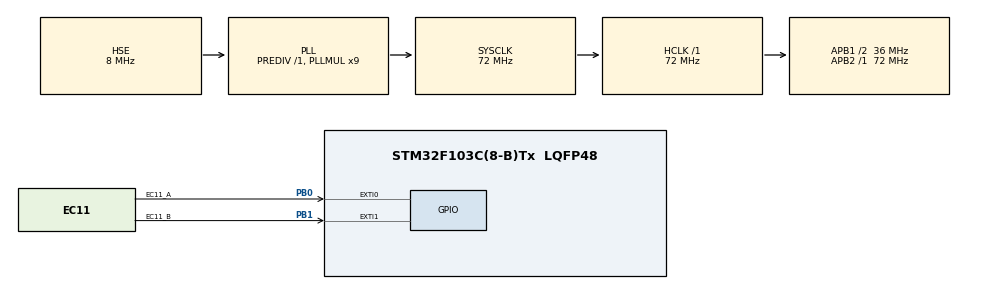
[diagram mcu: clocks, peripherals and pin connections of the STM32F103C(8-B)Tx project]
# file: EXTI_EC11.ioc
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Mcu.Family=STM32F1
Mcu.Name=STM32F103C(8-B)Tx
Mcu.Package=LQFP48
NVIC.EXTI0_IRQn=true\:0\:0\:false\:false\:true\:true\:true\:true
NVIC.EXTI1_IRQn=true\:0\:0\:false\:false\:true\:true\:true\:true
NVIC.PriorityGroup=NVIC_PRIORITYGROUP_4
PA13.Mode=Serial_Wire
PA13.Signal=SYS_JTMS-SWDIO
PA14.Mode=Serial_Wire
PA14.Signal=SYS_JTCK-SWCLK
PB0.GPIO_Label=EC11_A
PB0.GPIO_ModeDefaultEXTI=GPIO_MODE_IT_RISING_FALLING
PB0.GPIO_PuPd=GPIO_PULLUP
PB0.Signal=GPXTI0
PB1.GPIO_Label=EC11_B
PB1.GPIO_ModeDefaultEXTI=GPIO_MODE_IT_RISING_FALLING
PB1.GPIO_PuPd=GPIO_PULLUP
PB1.Signal=GPXTI1
PC14-OSC32_IN.Mode=LSE-External-Oscillator
PC14-OSC32_IN.Signal=RCC_OSC32_IN
PC15-OSC32_OUT.Mode=LSE-External-Oscillator
PC15-OSC32_OUT.Signal=RCC_OSC32_OUT
PD0-OSC_IN.Mode=HSE-External-Oscillator
PD0-OSC_IN.Signal=RCC_OSC_IN
PD1-OSC_OUT.Mode=HSE-External-Oscillator
PD1-OSC_OUT.Signal=RCC_OSC_OUT
ProjectManager.HeapSize=0x200
ProjectManager.StackSize=0x400
ProjectManager.TargetToolchain=CMake
RCC.AHBFreq_Value=72000000
RCC.APB1CLKDivider=RCC_HCLK_DIV2
RCC.APB1Freq_Value=36000000
RCC.APB1TimFreq_Value=72000000
RCC.APB2Freq_Value=72000000
RCC.APB2TimFreq_Value=72000000
RCC.HCLKFreq_Value=72000000
RCC.PLLMUL=RCC_PLL_MUL9
RCC.PLLSourceVirtual=RCC_PLLSOURCE_HSE
RCC.SYSCLKFreq_VALUE=72000000
RCC.SYSCLKSource=RCC_SYSCLKSOURCE_PLLCLK
RCC.USBFreq_Value=72000000
board=custom

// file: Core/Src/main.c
/* USER CODE BEGIN Header */
/**
  ******************************************************************************
  * @file           : main.c
  * @brief          : Main program body
  ******************************************************************************
  * @attention
  *
  * Copyright (c) 2026 STMicroelectronics.
  * All rights reserved.
  *
  * This software is licensed under terms that can be found in the LICENSE file
  * in the root directory of this software component.
  * If no LICENSE file comes with this software, it is provided AS-IS.
  *
  ******************************************************************************
  */
/* USER CODE END Header */
#include "main.h"
#include "gpio.h"
#include "OLED.h"

/* USER CODE BEGIN PV */
static volatile int32_t EC11_Count = 0;
static volatile int8_t EC11_QuarterSteps = 0;
static uint8_t EC11_PreviousState = 0;
static uint32_t lastDisplayTick = 0;

/* USER CODE END PV */

void SystemClock_Config(void);

int main(void) {

    /* MCU Configuration--------------------------------------------------------*/

    /* Reset of all peripherals, Initializes the Flash interface and the Systick. */
    HAL_Init();

    /* Configure the system clock */
    SystemClock_Config();

    /* Initialize all configured peripherals */
    MX_GPIO_Init();
    /* USER CODE BEGIN 2 */
    EC11_PreviousState = EC11_ReadState(); // 初始化编码器的初始状态

    OLED_Init();
    OLED_ShowString(1, 1, "EC11 Encoder");
    OLED_ShowString(2, 1, "CT:");

    /* USER CODE END 2 */

    /* Infinite loop */
    while (1) {

        /* USER CODE BEGIN 3 */
        if ((HAL_GetTick() - lastDisplayTick) >= 100U) {
            int32_t count = EC11_Count;
            lastDisplayTick = HAL_GetTick();
            OLED_ShowSignedNum(2, 4, count, 6);
        }
    }
    /* USER CODE END 3 */
}

void SystemClock_Config(void) {
    RCC_OscInitTypeDef RCC_OscInitStruct = {0};
    RCC_ClkInitTypeDef RCC_ClkInitStruct = {0};

    /** Initializes the RCC Oscillators according to the specified parameters
  * in the RCC_OscInitTypeDef structure.
  */
    RCC_OscInitStruct.OscillatorType = RCC_OSCILLATORTYPE_HSE;
    RCC_OscInitStruct.HSEState = RCC_HSE_ON;
    RCC_OscInitStruct.HSEPredivValue = RCC_HSE_PREDIV_DIV1;
    RCC_OscInitStruct.HSIState = RCC_HSI_ON;
    RCC_OscInitStruct.PLL.PLLState = RCC_PLL_ON;
    RCC_OscInitStruct.PLL.PLLSource = RCC_PLLSOURCE_HSE;
    RCC_OscInitStruct.PLL.PLLMUL = RCC_PLL_MUL9;
    if (HAL_RCC_OscConfig(&RCC_OscInitStruct) != HAL_OK) {
        Error_Handler();
    }

    /** Initializes the CPU, AHB and APB buses clocks
  */
    RCC_ClkInitStruct.ClockType =
        RCC_CLOCKTYPE_HCLK | RCC_CLOCKTYPE_SYSCLK | RCC_CLOCKTYPE_PCLK1 | RCC_CLOCKTYPE_PCLK2;
    RCC_ClkInitStruct.SYSCLKSource = RCC_SYSCLKSOURCE_PLLCLK;
    RCC_ClkInitStruct.AHBCLKDivider = RCC_SYSCLK_DIV1;
    RCC_ClkInitStruct.APB1CLKDivider = RCC_HCLK_DIV2;
    RCC_ClkInitStruct.APB2CLKDivider = RCC_HCLK_DIV1;

    if (HAL_RCC_ClockConfig(&RCC_ClkInitStruct, FLASH_LATENCY_2) != HAL_OK) {
        Error_Handler();
    }
}

/* USER CODE BEGIN 4 */
void HAL_GPIO_EXTI_Callback(uint16_t GPIO_Pin) {
    // 根据编码器的A相和B相的状态变化来更新计数值
    static const int8_t transitionTable[16] = {0, 1, -1, 0, -1, 0, 0, 1, 1, 0, 0, -1, 0, -1, 1, 0};

    if ((GPIO_Pin == EC11_A_Pin) || (GPIO_Pin == EC11_B_Pin)) {
        uint8_t currentState = EC11_ReadState(); // 读取当前编码器状态
        uint8_t transition = (uint8_t)((EC11_PreviousState << 2)| currentState); // 计算状态转换
        int8_t step = transitionTable
            [transition]; // 查表获取步进值，step为1表示顺时针，step为-1表示逆时针，step为0表示无效状态

        EC11_PreviousState = currentState; // 更新上一个状态
        EC11_QuarterSteps += step;

        // 顺时针旋转时，EC11_QuarterSteps增加；逆时针旋转时，EC11_QuarterSteps减少
        if (EC11_QuarterSteps >= 4) {
            if (EC11_Count < 999999) {
                EC11_Count++;
            }
            EC11_QuarterSteps = 0;
        } else if (EC11_QuarterSteps <= -4) {
            if (EC11_Count > -999999) {
                EC11_Count--;
            }
            EC11_QuarterSteps = 0;
        }
    }
}

/* USER CODE END 4 */

void Error_Handler(void) {
    __disable_irq();
    while (1) {
    }
}
